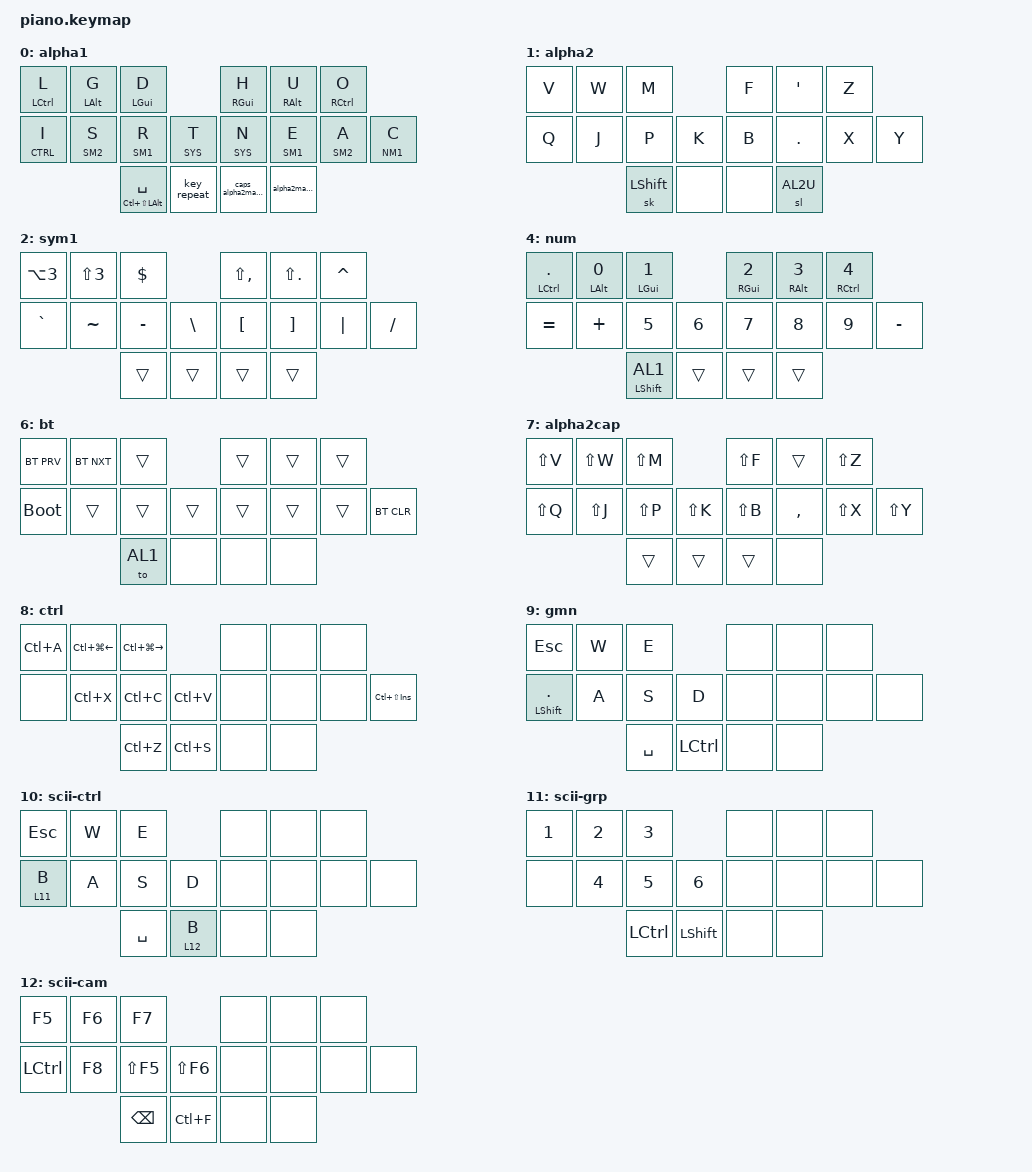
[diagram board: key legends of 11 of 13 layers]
/*
 * Copyright (c) 2020 The ZMK Contributors
 *
 * SPDX-License-Identifier: MIT
 */

#include <behaviors.dtsi>
#include <dt-bindings/zmk/keys.h>
#include <dt-bindings/zmk/bt.h>
#include <dt-bindings/zmk/mouse.h>



&mt {
    tapping-term-ms = <201>;
    flavor = "tap-preferred";
 };
&sk {
     release-after-ms = <2000>;
     quick-release;
 };
 
/* Layers */
#define AL1 0
#define AL2 1
#define SM1 2
#define SM2 3	
#define NM1 4	
#define SYS 5
#define BT 6	
#define AL2U 7
#define CTRL 8
#define GMN 9
#define SCCTRL 10
#define SCGRP 11
#define SCCAM 12

/ { 
    combos {
        compatible = "zmk,combos";
        combo_gmn {
            timeout-ms = <30>;
	    key-positions = <7 1 9>;
            bindings = <&to GMN>;
        };
        combo_sc {
            timeout-ms = <30>;
	    key-positions = <3 5>;
            bindings = <&to SCCTRL>;
	    			layers = <GMN>; 
        };
        combo_sys {
            timeout-ms = <30>;
	    key-positions = <3 4 5>;
            bindings = <&to SYS>;
        };
        combo_caps {
            timeout-ms = <30>;
	    key-positions = <10 11 12>;
            bindings = <&caps_word>;
        };
        combo_bt  {
            timeout-ms = <10>;
            key-positions = <11 12>;
            bindings = <&to BT>;
	    layers = <SM1>; 
        };
        lalt {
            timeout-ms = <20>;
	    key-positions = <8 9>;
            bindings = <&kp LALT>; 
	    layers = <SYS>; 
        };
        lclk {
            timeout-ms = <20>;
	    key-positions = <10 11>;
            bindings = <&mkp LCLK>;
	    layers = <SYS>;
        };
        rclk {
            timeout-ms = <20>;
	    key-positions = <3 4>;
            bindings = <&mkp RCLK>;
	    layers = <SYS>;
        };


    };

    behaviors {
        hm_l: homerow_mods_left {
            compatible = "zmk,behavior-hold-tap";
            label = "HOMEROW_MODS_L";
            #binding-cells = <2>;
            tapping-term-ms = <300>;
            quick-tap-ms = <250>;
            flavor = "tap-preferred";
            bindings = <&kp>, <&kp>;
	    hold-trigger-key-positions = <3 4 5 10 11 12 13 14>; // right hand
        };
        hm_r: homerow_mods_right {
            compatible = "zmk,behavior-hold-tap";
            label = "HOMEROW_MODS_R";
            #binding-cells = <2>;
            tapping-term-ms = <300>;
            quick-tap-ms = <250>;
            flavor = "tap-preferred";
            bindings = <&kp>, <&kp>;
	    hold-trigger-key-positions = <0 1 2 6 7 8 9>; // left hand
        };
        sr: shift_layer {
            compatible = "zmk,behavior-hold-tap";
            label = "SHIFT_LAYER";
            #binding-cells = <2>;
            tapping-term-ms = <300>;
            quick_tap_ms = <0>;
            flavor = "tap-preferred";
            bindings = <&kp>, <&to>;
	    retro-tap;
        };
        hl_l: homerow_layers_left {
            compatible = "zmk,behavior-hold-tap";
            label = "HOMEROW_LAYERS_L";
            #binding-cells = <2>;
            tapping-term-ms = <220>;
            quick-tap-ms = <250>;
            flavor = "tap-preferred";
            bindings = <&mo>, <&kp>;
	    hold-trigger-key-positions = <3 4 5 10 11 12 13 14>; // right hand
        };
        hl_r: homerow_layers_right {
            compatible = "zmk,behavior-hold-tap";
            label = "HOMEROW_LAYERS_R";
            #binding-cells = <2>;
            tapping-term-ms = <220>;
            quick-tap-ms = <250>;
            flavor = "tap-preferred";
            bindings = <&mo>, <&kp>;
	    hold-trigger-key-positions = <0 1 2 6 7 8 9>; // left hand
        };
	td: tapdance {
            compatible = "zmk,behavior-hold-tap";
            label = "TAPDANCE";
            #binding-cells = <2>;
            tapping-term-ms = <190>;
            quick-tap-ms = <250>;
            flavor = "tap-preferred";
            bindings = <&kp>, <&kp>;
        };
	alpha2macro: behavior_macro_1 {
		compatible = "zmk,behavior-macro";
		label = "MACRO1";
		#binding-cells = <0>;
		bindings = < &sl AL2 >;
	};
	caps_alpha2macro: behavior_macro_2 {
		compatible = "zmk,behavior-macro";
		label = "MACRO2";
		#binding-cells = <0>;
		bindings = < &sl AL2U >;
	};
	sccammacro: behavior_macro_3 {
		compatible = "zmk,behavior-macro";
		label = "MACRO3";
		#binding-cells = <0>;
		bindings = < &sl SCCAM >;
	};
    };
// 				0		1		2					3		4			5
// 		6		7		8		9 					10		11			12 		13
//								14	15 	16 	17		
       keymap {
                compatible = "zmk,keymap";
                
       		alpha1 {
		bindings = <
		 		&hm_l LCTL L 	&hm_l LALT G 	&hm_l LGUI D		&hm_r RGUI H 	&hm_r RALT U    	&hm_r RCTL O	  
		&hl_l CTRL I	&hl_l SM2 S	&hl_l SM1 R	&hl_l SYS T 	 	&hl_r SYS N    	&hl_r SM1 E   		&hl_r SM2 A 	&hl_r NM1 C
			 	 		 		&mt LC(LS(LALT)) SPC &key_repeat  &caps_alpha2macro	&alpha2macro	 	
		>;
		};
       		alpha2 {
		bindings = <
		 	 	&kp V 		&kp W		&kp M	 	 	&kp F    	&kp SQT			&kp Z 		
		&kp Q	 	&kp J 		&kp P		&kp K 			&kp B 		&kp DOT			&kp X		&kp Y 
			 	 		 		&sk LSHIFT 		&none &none &sl AL2U	
		>;
		};
		
       		sym1 {
		bindings = <
		 		&kp LA(N3)   	&kp LS(N3)	&kp DLLR	    	&kp LS(COMMA)	&kp LS(DOT)		&kp CARET	
		&kp GRAVE	&kp TILDE 	&kp MINUS      	&kp BSLH	 	&kp LBKT	&kp RBKT	 	&kp PIPE 	&kp SLASH
				  				&trans  		&trans		&trans  	&trans
		>;
		};
		sym2 {
		bindings = <
				&kp ATSN	&td LA(RBKT) LA(LS(RBKT))	&td  LA(LBKT) LA(LS(LBKT))	&kp LPRN	&kp RPRN 	&kp SEMI 	
		&kp STAR  	&kp PRCNT	&td QMARK EXCL       		&kp DQT   			&kp LBRC  	&kp RBRC	&kp AMPS	&kp COLON 
		 		&trans 		&trans  			&trans 	&none &none &trans 		

		>;
		};

		num {
		bindings = <
				&hm_l LCTL DOT 	&hm_l LALT N0	&hm_l LGUI N1 		&hm_r RGUI N2 	&hm_r RALT N3		&hm_r RCTL N4	
		&kp EQUAL	&kp PLUS 	&kp N5		&kp N6			&kp N7		&kp N8			&kp N9   	&kp MINUS
							&sr LSHIFT AL1 		&trans 		&trans 			&trans  	 
		>;
		};

		sys {
		bindings = <
				 	&kp ESC			&kp LC(LS(TAB)) 	&kp RC(TAB)		&td LG(V) LG(D) 	&kp UP 		&td Q BKSP 			
		&td LG(GRAVE) TAB	&td HOME DEL		&td END LC(C) 	&kp LC(V)		&td TAB LEFT  		&kp DOWN 	&td  LC(LG(LS(N4))) RIGHT 	&kp RET 
		 			 		 				&sr LSHIFT AL1 		&none &none &kp RGUI		
		>;
		};

		bt {
		bindings = <
				&bt BT_PRV	&bt BT_NXT	&trans 			&trans 	&trans	&trans	
		&bootloader  	&trans 		&trans 		&trans 			&trans 	&trans 	&trans	&bt BT_CLR
		 	 	 				&to AL1	&none &none	&none
		>;
		};

       		alpha2cap {
		bindings = <
		 	 	&kp LS(V)	&kp LS(W)	&kp LS(M) 	 	&kp LS(F)    	&trans		&kp LS(Z)	
		&kp LS(Q) 	&kp LS(J) 	&kp LS(P)	&kp LS(K)		&kp LS(B)	&kp COMMA	&kp LS(X)	&kp LS(Y) 
			 	&trans 		&trans 			&trans	&none
		>;
		};

		ctrl {
		bindings = <
				 	&kp LC(A)  &kp LC(LG(LEFT)) &kp LC(LG(RIGHT))	&none 	&none 		&none 			
		&none	&kp LC(X) &kp LC(C) 	&kp LC(V)		&none  	&none 	&none &kp LC(LS(INS)) 
		 			 		 				&kp LC(Z) &kp LC(S)   &none &none		
		>;
		};

		gmn {
		bindings = <
				 	&kp ESC  &kp W &kp E	&none 	&none 		&none 			
		&hm_l LSHIFT DOT &kp A &kp S &kp D		&none  	&none 	&none &none
		 			 		 				&kp SPC &kp LCTL   &none &none		
		>;
		};

		scii-ctrl {
		bindings = <
				 	&kp ESC  &kp W &kp E	&none 	&none 		&none 			
		 &lt 11 B &kp A &kp S &kp D		&none  	&none 	&none &none
		 			 		 				&kp SPC &lt 12 B    &none &none		
		>;
		};

		scii-grp {
		bindings = <
				 	&kp N1 &kp N2 &kp N3	&none 	&none 		&none 			
		 &none &kp N4 &kp N5 &kp N6	&none  	&none 	&none &none
		 			 		 				&kp LCTL &kp LSHIFT &none &none		
		>;
		};

		scii-cam {
		bindings = <
				 	&kp F5 &kp F6 &kp F7	&none 	&none 		&none 			
		 &kp LCTL &kp F8 &kp LS(F5) &kp LS(F6)	&none  	&none 	&none &none
		 			 		 				&kp BKSP &kp LC(F) &none &none		
		>;
		};
        
	};
};
